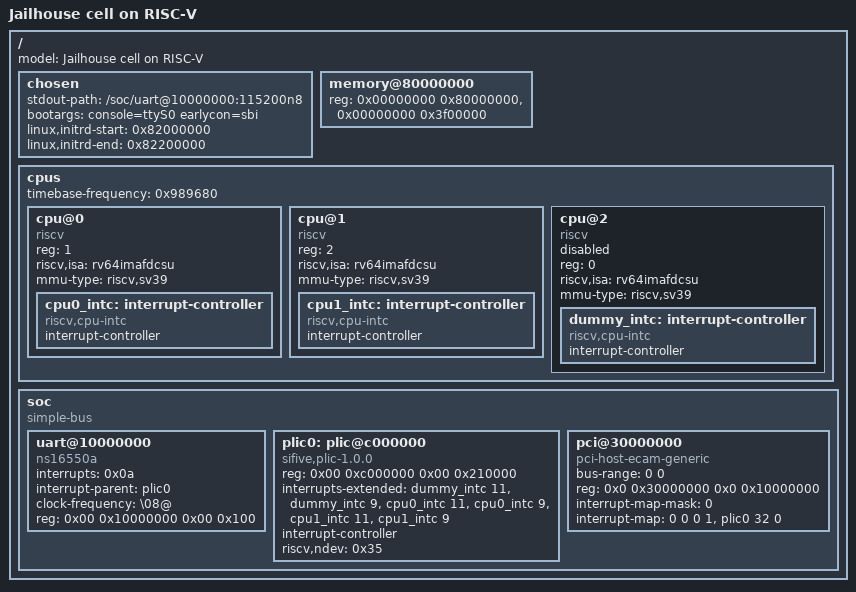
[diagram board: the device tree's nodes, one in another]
/*
 * Jailhouse, a Linux-based partitioning hypervisor
 *
 * Copyright (c) OTH Regensburg, 2022
 *
 * Authors:
 *  Ralf Ramsauer <ralf.ramsauer@oth-regensburg.de>
 *
 * This work is licensed under the terms of the GNU GPL, version 2.  See
 * the COPYING file in the top-level directory.
 */

/dts-v1/;
/ {
	model = "Jailhouse cell on RISC-V";

	#address-cells = <2>;
	#size-cells = <2>;

	chosen {
		stdout-path = "/soc/uart@10000000:115200n8";
		bootargs = "console=ttyS0 earlycon=sbi";
		linux,initrd-start = <0x82000000>;
		linux,initrd-end = <0x82200000>;
	};

	memory@80000000 {
		device_type = "memory";
		/* 63MiB @ 0x80000000 */
		reg = <0x00000000 0x80000000>, <0x00000000 0x3f00000>;
	};

	cpus {
		#address-cells = <1>;
		#size-cells = <0>;
		timebase-frequency = <0x989680>;

		cpu@0 {
			device_type = "cpu";
			reg = <1>;
			status = "okay";
			compatible = "riscv";
			riscv,isa = "rv64imafdcsu";
			mmu-type = "riscv,sv39";

			cpu0_intc: interrupt-controller {
				#address-cells = <0>;
				#interrupt-cells = <1>;
				interrupt-controller;
				compatible = "riscv,cpu-intc";
			};
		};

		cpu@1 {
			device_type = "cpu";
			reg = <2>;
			status = "okay";
			compatible = "riscv";
			riscv,isa = "rv64imafdcsu";
			mmu-type = "riscv,sv39";

			cpu1_intc: interrupt-controller {
				#address-cells = <0>;
				#interrupt-cells = <1>;
				interrupt-controller;
				compatible = "riscv,cpu-intc";
			};
		};

		cpu@2 {
			device_type = "cpu";
			reg = <0>;
			status = "disabled";
			compatible = "riscv";
			riscv,isa = "rv64imafdcsu";
			mmu-type = "riscv,sv39";

			dummy_intc: interrupt-controller {
				#address-cells = <0>;
				#interrupt-cells = <1>;
				interrupt-controller;
				compatible = "riscv,cpu-intc";
			};
		};
	};
	soc {
		#address-cells = <2>;
		#size-cells = <2>;
		compatible = "simple-bus";
		ranges;

		uart@10000000 {
			interrupts = <0x0a>;
			interrupt-parent = <&plic0>;
			clock-frequency = "\08@";
			reg = <0x00 0x10000000 0x00 0x100>;
			compatible = "ns16550a";
			status = "okay";
		};

		plic0: plic@c000000 {
			reg = <0x00 0xc000000 0x00 0x210000>;
			interrupts-extended = <
				&dummy_intc 11
				&dummy_intc 9
				&cpu0_intc 11
				&cpu0_intc 9
				&cpu1_intc 11
				&cpu1_intc 9
			>;
			interrupt-controller;
			compatible = "sifive,plic-1.0.0\0riscv,plic0";
			riscv,ndev = <0x35>;
			#interrupt-cells = <0x01>;
			#address-cells = <0x00>;
		};

		pci@30000000 {
			compatible = "pci-host-ecam-generic";
			device_type = "pci";
			bus-range = <0 0>;
			#interrupt-cells = <1>;
			reg = <0x0 0x30000000 0x0 0x10000000>;
			#address-cells = <3>;
			#size-cells = <2>;
			ranges = <
				0x1000000 0x00 0x00 0x00 0x3000000 0x00 0x10000
				0x2000000 0x00 0x40000000 0x00 0x40000000 0x00 0x40000000
				0x3000000 0x04 0x00 0x04 0x00 0x04 0x00>;

			interrupt-map-mask = <0>;
			interrupt-map = <0 0 0 1 &plic0 32 0>;
		};
	};
};
